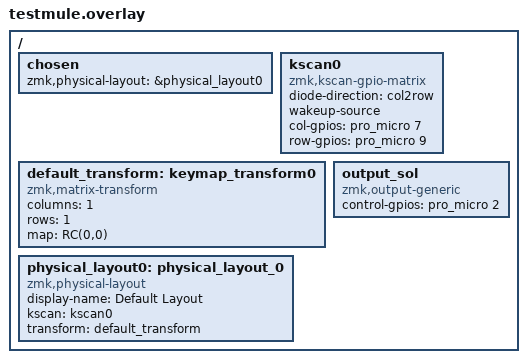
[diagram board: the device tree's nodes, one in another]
#include <dt-bindings/zmk/matrix_transform.h>

/ {
    chosen {
        zmk,physical-layout = &physical_layout0;
        // Other chosen items
    };

    kscan0: kscan0 {
        compatible = "zmk,kscan-gpio-matrix";
        diode-direction = "col2row";
        wakeup-source;

        col-gpios
            = <&pro_micro 7 GPIO_ACTIVE_HIGH>
            ;

        row-gpios
            = <&pro_micro 9 (GPIO_ACTIVE_HIGH | GPIO_PULL_DOWN)>
            ;
    };

	default_transform: keymap_transform0 {
        compatible = "zmk,matrix-transform";
        columns = <1>; // Length of the "col-gpios" array
        rows = <1>; // Length of the "row-gpios" array
        map = <
            RC(0,0)
        >;
    };

	physical_layout0: physical_layout_0 { // First physical layout, use different naming for other layouts
        compatible = "zmk,physical-layout";
        display-name = "Default Layout";
        kscan = <&kscan0>; // Label of the kscan node, optional if all layouts use the same
        transform = <&default_transform>; // Label of the matrix transform for this layout
    };

    output_sol: output_sol {
		compatible = "zmk,output-generic";
		#binding-cells = <0>;
		control-gpios = <&pro_micro 2 GPIO_ACTIVE_HIGH>;
	};
};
